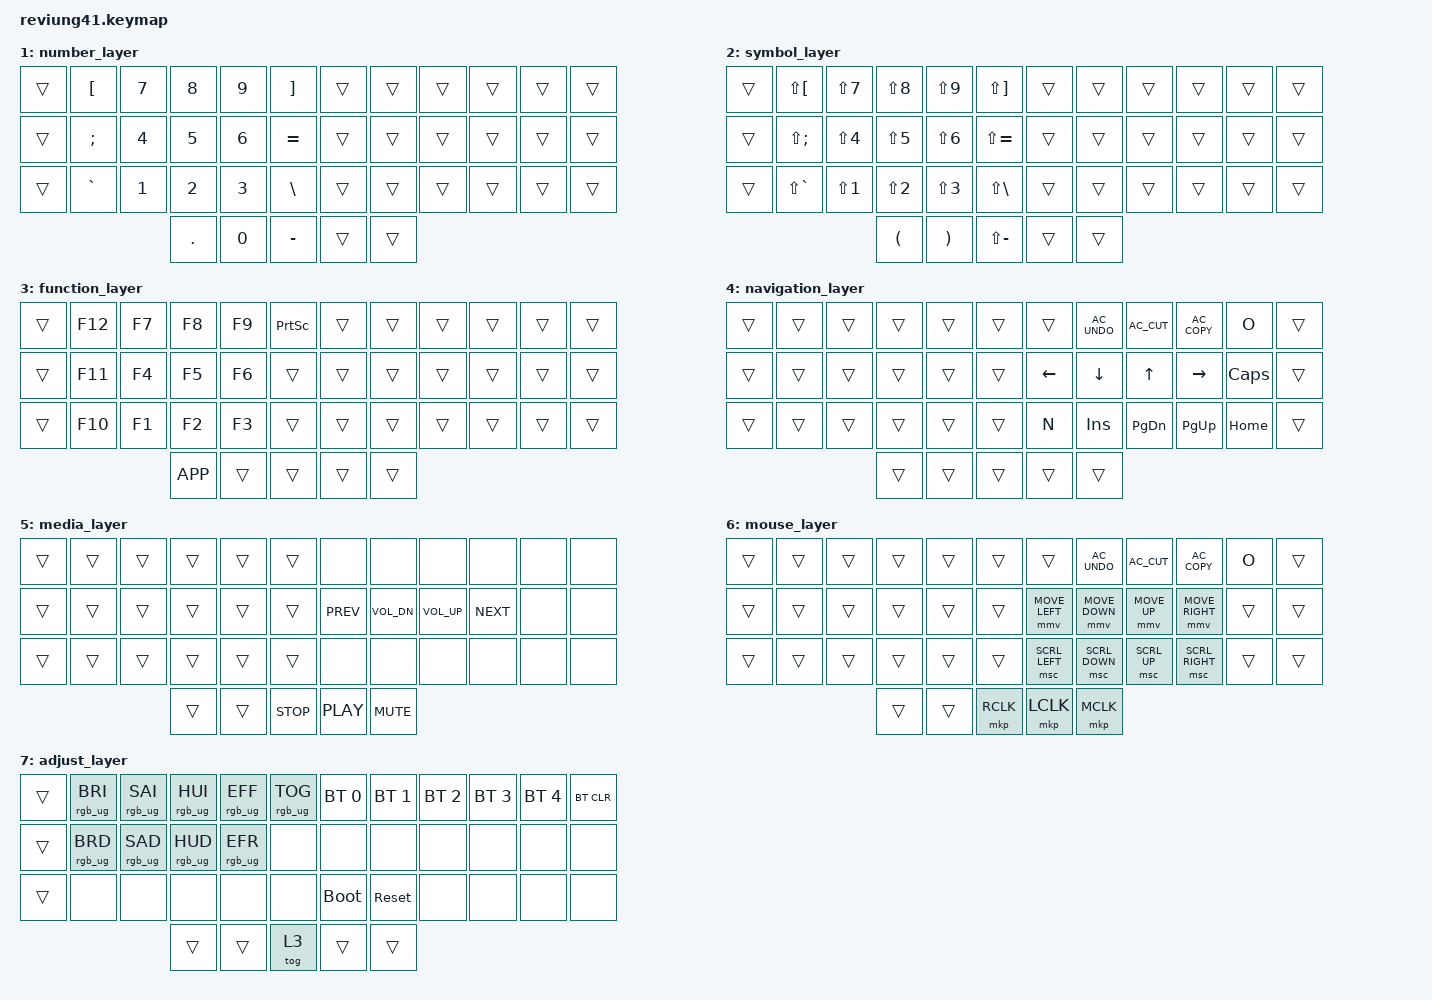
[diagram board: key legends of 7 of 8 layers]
/*
 * Copyright (c) 2020 The ZMK Contributors
 *
 * SPDX-License-Identifier: MIT
 * 
 * This layer is oriented at https://github.com/manna-harbour/miryoku_zmk
*/

#include <behaviors.dtsi>
#include <dt-bindings/zmk/keys.h>
#include <dt-bindings/zmk/bt.h>
#include <dt-bindings/zmk/rgb.h>
#include <dt-bindings/zmk/pointing.h>


#define DFA 0  // Default layer
#define NUB 1  // Number layer
#define SYM 2  // Symbol layer
#define FUN 3  // Function layer
#define NAV 4  // Navigation layer
#define MED 5  // Media layer
#define MOS 6  // Mouse layer
#define ADJ 7  // Adjustment layer
#define NUL 8  // NumLock layer

// define thumb keys
#define MosTab &lt MOS TAB
#define SymEnter &lt SYM ENTER
#define NavSpc &lt NAV SPACE
#define FunDel &lt FUN DEL
#define MedEsc &lt MED ESC
#define NumBckSpc &lt NUB BACKSPACE

// define ALt right (for Umlaute)
#define alt_r(key) &mt RALT key

// Left-hand home-row mod helper.
// Usage: hrm_l(K1, K2, K3, K4) assigns Super, Alt, Shift, Ctrl left-to-right.
// Any keycodes work, e.g. hrm_l(Q, W, E, R) or hrm_l(A, S, D, F).
#define hrm_l(key1,key2,key3,key4) &mt LGUI key1 &mt LALT key2 &mt LSHIFT key3 &mt LCTRL key4

// Right-hand home-row mod helper.
// Usage: hrm_r(K1, K2, K3, K4) assigns  Ctrl, Shift, Alt, Super left-to-right.
// Any keycodes work, e.g. hrm_r(J, K, K, L)
#define hrm_r(key1,key2,key3,key4) &mt LCTRL key1 &mt RSHIFT key2 &mt LALT key3 &mt LGUI key4

/ {
        keymap {
                compatible = "zmk,keymap";

                default_layer {
// -------------------------------------------------------------------------------------
// |  ADJ |  Q  |  W  |  E  |  R    |  T  |   |  Y  |  U    |  I  |  O  |  P  |   BSPC    |
// | CTRL |  A  |  S  |  D  |  F    |  G  |   |  H  |  J    |  K  |  L  |  ;  |    '      |
// |MosTab|  Z  |  X  |  C  |AltR(V)|  B  |   |  N  |AltR(M)|  ,  |  .  |  /  |  Shift    |
//                 | MedEsc | MedEsc | NavSpc | SymEnter  | NumBckSpc |
                        bindings = <
   &mo ADJ   &kp Q &kp W &kp E &kp R    &kp T   &kp Y &kp U    &kp I     &kp O   &kp P    &kp BSPC
   &kp LCTRL hrm_l(A, S, D, F)          &kp G   &kp H hrm_r(J, K, L, SEMI)                &kp SQT
   MosTab    &kp Z &kp X &kp C alt_r(V) &kp B   &kp N alt_r(M) &kp COMMA &kp DOT &kp FSLH &kp RSHFT 
                             MedEsc NavSpc SymEnter NumBckSpc FunDel
                        >;
                };

                number_layer {
// -------------------------------------------------------------------------------------
// |  ADJ |  [  |  7  |  8  |  9  |  ]  |   |  Y  |  U   |  I  |  O  |  P  |   BSPC    |
// | CTRL |  ;  |  4  |  5  |  6  |  =  |   |  H  |  J   |  K  |  L  |  ;  |    '      |
// | RAlt |  `  |  1  |  2  |  3  |  \  |   |  N  |  M   |  ,  |  .  |  /  |  FunDel   |
//                              | . | 0 | - | SymEnter | NumBckSp |
                        bindings = <
   &trans &kp LBKT  &kp N7 &kp N8 &kp N9 &kp RBKT  &trans &trans &trans &trans &trans &trans
   &trans &kp SEMI  &kp N4 &kp N5 &kp N6 &kp EQUAL &trans &trans &trans &trans &trans &trans
   &trans &kp GRAVE &kp N1 &kp N2 &kp N3 &kp BSLH  &trans &trans &trans &trans &trans &trans
                             &kp DOT &kp N0 &kp MINUS &trans &trans
                        >;
                };

                symbol_layer {
// -----------------------------------------------------------------------------------
// |    |  {  |  &  |  *  |  (  |  }  |   |  Y  |  U   |  I  |  O  |  P  |   BSPC    |
// |    |  :  |  $  |  %  |  ^  | +   |   |  H  |  J   |  K  |  L  |  ;  |    '      |
// |    |  ~  |  !  |  @  |  #  | "|" |   |  N  |  M   |  ,  |  .  |  /  |  FunDel   |
//                 | ( | ) | _ | SymEnter | NumBckSpc |
                        bindings = <
   &trans &kp LS(LBKT)  &kp LS(N7) &kp LS(N8) &kp LS(N9) &kp LS(RBKT)    &trans &trans &trans &trans &trans &trans
   &trans &kp LS(SEMI)  &kp LS(N4) &kp LS(N5) &kp LS(N6) &kp LS(EQUAL)   &trans &trans &trans &trans &trans &trans
   &trans &kp LS(GRAVE) &kp LS(N1) &kp LS(N2) &kp LS(N3) &kp LS(BSLH)    &trans &trans &trans &trans &trans &trans
                                        &kp LPAR &kp RPAR &kp LS(MINUS) &trans &trans
                        >;
                };

                function_layer {
// ---------------------------------------------------------------------------------------
// |  ADJ | F12 | F7  | F8  | F9  | PSCRN |   |  Y  |  U   |  I  |  O  |  P  |   BSPC    |
// | CTRL | F11 | F4  | F5  | F6  |  G    |   |  H  |  J   |  K  |  L  |  ;  |    '      |
// | RAlt | F10 | F1  | F2  | F3  |  B    |   |  N  |  M   |  ,  |  .  |  /  |  FunDel   |
//                 | APP_menu | MedEsc | NavSpc | SymEnter | NumBckSpc |
                        bindings = <
   &trans &kp F12  &kp F7 &kp F8 &kp F9 &kp PSCRN &trans &trans &trans &trans &trans &trans
   &trans &kp F11  &kp F4 &kp F5 &kp F6 &trans    &trans &trans &trans &trans &trans &trans
   &trans &kp F10  &kp F1 &kp F2 &kp F3 &trans    &trans &trans &trans &trans &trans &trans
                             &kp K_APP &trans &trans &trans &trans
                        >;
                };

                navigation_layer {
// -------------------------------------------------------------------------------------
// |  ADJ |  Q  |  W  |  E  |  R  |  T  |   |  Y  | Undo | Cut  | Copy | Past |   BSPC    |
// | CTRL |  A  |  S  |  D  |  F  |  G  |   |  <- | down | up   |  ->  | CAPS |    '      |
// | RAlt |  Z  |  X  |  C  |  V  |  B  |   |  N  | Ins  | Pg_dn| Pg_up| Home |  FunDel   |
//                 | MosTab | MedEsc | NavSpc | SymEnter | NumBckSpc |
                        bindings = <
   &trans &trans &trans &trans &trans &trans   &trans   &kp C_AC_UNDO &kp C_AC_CUT &kp C_AC_COPY &kp O    &trans
   &trans &trans &trans &trans &trans &trans   &kp LEFT &kp DOWN      &kp UP       &kp RIGHT     &kp CAPS &trans
   &trans &trans &trans &trans &trans &trans   &kp N    &kp INSERT    &kp PG_DN    &kp PG_UP     &kp HOME &trans
                             &trans &trans &trans &trans &trans
                        >;
                };

                media_layer {
// -------------------------------------------------------------------------------------
// |  ADJ |  Q  |  W  |  E  |  R  |  T  |   |  no |  no  |  no  |  no  |  no  |   no   |
// | CTRL |  A  |  S  |  D  |  F  |  G  |   | prev| vol- | vol+ | next |  no  |   no   |
// | RAlt |  Z  |  X  |  C  |  V  |  B  |   |  no |  no  |  no  |  no  |  no  |   no   |
//                  | MosTab | MedEsc | Stop | Play | Mute |
                        bindings = <
   &trans &trans &trans &trans &trans &trans   &none      &none        &none        &none      &none &none
   &trans &trans &trans &trans &trans &trans   &kp C_PREV &kp C_VOL_DN &kp C_VOL_UP &kp C_NEXT &none &none
   &trans &trans &trans &trans &trans &trans   &none      &none        &none        &none      &none &none
                             &trans &trans &kp C_STOP &kp C_PLAY &kp C_MUTE
                        >;
                };

                mouse_layer {
// -------------------------------------------------------------------------------------
// |  ADJ |  Q  |  W  |  E  |  R  |  T  |   |  Y  | Undo | Cut  | Copy | Past |   BSPC |
// | CTRL |  A  |  S  |  D  |  F  |  G  |   |ms_l | ms_d | ms_u | ms_r |  no  |   no   |
// | RAlt |  Z  |  X  |  C  |  V  |  B  |   |wh_l |wh_d  | wh_u | wh_r | end  |   no   |
//                  | MosTab | MedEsc | BTN2 | BTN1 | BTN3 |
                        bindings = <
   &trans &trans &trans &trans &trans &trans   &trans         &kp C_AC_UNDO  &kp C_AC_CUT &kp C_AC_COPY   &kp O  &trans
   &trans &trans &trans &trans &trans &trans   &mmv MOVE_LEFT &mmv MOVE_DOWN &mmv MOVE_UP &mmv MOVE_RIGHT &trans &trans
   &trans &trans &trans &trans &trans &trans   &msc SCRL_LEFT &msc SCRL_DOWN &msc SCRL_UP &msc SCRL_RIGHT &trans &trans
                             &trans &trans &mkp RCLK &mkp LCLK &mkp MCLK
                        >;
                };

                adjust_layer {
// -----------------------------------------------------------------------------------------
// | --- | RGB BRI+ | RGB SAT+ | RGB HUE+ | RGB ANI+  | RGB TOG |   |  BT1     | BT2 | BT3 | BT4 | BT5 | BT CLR |
// | --- | RGB BRI- | RGB SAT- | RGB HUE- | RGB ANI-  |         |   |          |     |     |     |     |        |
// | --- |          |          |          |           |         |   |Bootloader|RESET|     |     |     |        |
//                                           |     |     |     |     |     |
                        bindings = <
 &trans  &rgb_ug RGB_BRI &rgb_ug RGB_SAI &rgb_ug RGB_HUI &rgb_ug RGB_EFF  &rgb_ug RGB_TOG    &bt BT_SEL 0 &bt BT_SEL 1 &bt BT_SEL 2 &bt BT_SEL 3 &bt BT_SEL 4 &bt BT_CLR
 &trans  &rgb_ug RGB_BRD &rgb_ug RGB_SAD &rgb_ug RGB_HUD &rgb_ug RGB_EFR  &none              &none        &none        &none        &none        &none        &none
 &trans  &none           &none           &none           &none            &none              &bootloader  &sys_reset   &none        &none        &none        &none
                                                             &trans      &trans       &tog 3        &trans      &trans
                        >;
                };
        };
};
